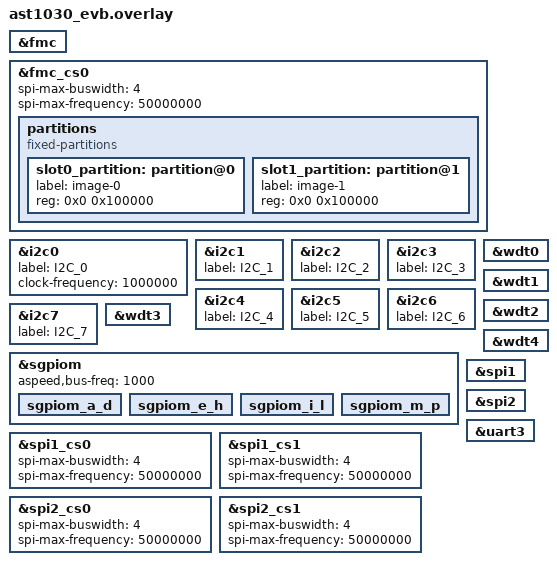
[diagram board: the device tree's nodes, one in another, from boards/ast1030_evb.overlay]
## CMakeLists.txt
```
# Copyright (c) 2026 ASPEED Technology Inc.
# SPDX-License-Identifier: MIT

cmake_minimum_required(VERSION 3.20.0)

find_package(Zephyr REQUIRED HINTS $ENV{ZEPHYR_BASE})
project(obmf-demo)

target_sources(app PRIVATE
    src/main.c
    src/lstp_usb.c
    src/lstp_router.c
    src/lstp_task.c
    src/lstp_i2c.c
    src/lstp_spi.c
    src/lstp_uart.c
)
```

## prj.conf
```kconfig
CONFIG_LOG=y
# CONFIG_LOG_MODE_IMMEDIATE=y
# CONFIG_LOG_DEFAULT_LEVEL=4
CONFIG_UART_CONSOLE_DEBUG_SERVER_HOOKS=y

# USB configuration
CONFIG_USB_DEVICE_STACK=y
CONFIG_USB_DEVICE_PRODUCT="OBMF Demo"
CONFIG_USB_DEVICE_VID=0x1ab4
CONFIG_USB_DEVICE_PID=0x0001
# Use same max EP buffer size as mctp-demo if 512 is supported, or fallback to 64 if HS is not enabled
CONFIG_USB_DEVICE_INITIALIZE_AT_BOOT=n
CONFIG_SHELL=y
CONFIG_SHELL_PROMPT_UART="ast1030-evb:~$ "
CONFIG_SHELL_STACK_SIZE=4096
CONFIG_SHELL_BACKEND_SERIAL_INIT_PRIORITY=99
CONFIG_SHELL_BACKEND_SERIAL_LOG_MESSAGE_QUEUE_TIMEOUT=-1
CONFIG_SHELL_BACKEND_SERIAL_LOG_MESSAGE_QUEUE_SIZE=1024

# I2C support for the OBMF I2C channel
CONFIG_I2C=y
CONFIG_UART_INTERRUPT_DRIVEN=y
```

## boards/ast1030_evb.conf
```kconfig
CONFIG_WATCHDOG=y
CONFIG_DYNAMIC_INTERRUPTS=y
CONFIG_GPIO_ASPEED_SGPIOM=y

CONFIG_SPI=y
CONFIG_SPI_ASPEED=y
CONFIG_SPI_NOR=n
CONFIG_SPI_NOR_MULTI_DEV=y
CONFIG_SPI_DMA_SUPPORT_ASPEED=y

CONFIG_FLASH=y
CONFIG_FLASH_JESD216_API=y
CONFIG_FLASH_PAGE_LAYOUT=y
CONFIG_FLASH_MAP=y
CONFIG_FLASH_SHELL=y

CONFIG_I2C=y
CONFIG_I2C_ASPEED=y
CONFIG_I2C_TARGET=y


CONFIG_USB_CDC_ACM=n
# For the NVIDIA OBMF USB host driver
CONFIG_USB_DEVICE_VID=0x0955
CONFIG_USB_DEVICE_PID=0xcf11
CONFIG_USB_DEVICE_MANUFACTURER="ASPEED"
CONFIG_USB_DEVICE_PRODUCT="OBMF-USB"
CONFIG_USB_DEVICE_SN="55661030"
CONFIG_USB_DEVICE_STACK=y
CONFIG_USB_REQUEST_BUFFER_SIZE=4096
# CONFIG_USB_DEVICE_LOG_LEVEL_OFF=y

CONFIG_I3C=y
CONFIG_I3C_TARGET=y
CONFIG_I3C_IBI_WORKQUEUE=y
CONFIG_I3C_SHELL=y
CONFIG_SHELL_GETOPT=y


CONFIG_MBEDTLS=n
CONFIG_MBEDTLS_SHA384=n
CONFIG_UART_ASPEED=y


CONFIG_JTAG=y
CONFIG_JTAG_ASPEED=y

CONFIG_USB_WORKQUEUE=y
```

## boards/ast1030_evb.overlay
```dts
&fmc {
	status = "okay";
};

&fmc_cs0 {
	status = "okay";
	spi-max-buswidth = <4>;
	spi-max-frequency = <50000000>;

	partitions {
		compatible = "fixed-partitions";
		#address-cells = <1>;
		#size-cells = <1>;
		slot0_partition: partition@0 {
			label = "image-0";
			reg = <0x0 0x100000>;
		};
		slot1_partition: partition@1 {
		       label = "image-1";
		       reg = <0x0 0x100000>;
	       };
	};
};

&i2c0 {
	status = "okay";
	label = "I2C_0";
	clock-frequency = <1000000>;
};

&i2c1 {
	status = "okay";
	label = "I2C_1";
};

&i2c2 {
	status = "okay";
	label = "I2C_2";
};

&i2c3 {
	status = "okay";
	label = "I2C_3";
};

&i2c4 {
	status = "okay";
	label = "I2C_4";
};

&i2c5 {
	status = "okay";
	label = "I2C_5";
};

&i2c6 {
	status = "okay";
	label = "I2C_6";
};

&i2c7 {
	status = "okay";
	label = "I2C_7";
};

&wdt0 {
	status = "okay";
};

&wdt1 {
	status = "okay";
};

&wdt2 {
	status = "okay";
};

&wdt3 {
	status = "okay";
};

&wdt4 {
	status = "okay";
};

/*
 * i3c0-to-i3c1 Loopback:
 * i3c0 plays the role as the bus controller
 * i3c1 plays the rols as the target device
 *
 * In I3C shell command, the following devices will be found:
 * i3c@7e7a2000 -> i3c0 controller
 * i3cdev@7ec80011000 -> the i3c device attached to i3c0 controller
 *
 * i3c@7e7a2000 -> i3c1 controller
 * i3c-tmq@7ec80011000 -> i3c target mqueue device
 */
// &i3c0 {
// 	status = "okay";
// 	label = "I3C_0";
// 	sda-tx-hold-ns = <20>;
// 	i3c-pp-scl-hi-period-ns = <250>;
// 	i3c-pp-scl-lo-period-ns = <250>;
//
// 	assigned-address = <0x30>;
//
// 	i3cdev@7ec80011000 {
// 		compatible = "i3c-dummy-device";
// 		reg = <0x0 0x7ec 0x80011000>;
// 		status = "okay";
// 	};
// };

// &i3c1 {
// 	secondary;
// 	dcr = <0xcc>;
// 	status = "okay";
// 	label = "I3C_1";
//
// 	assigned-address = <0x31>;
//
// 	i3c-tmq@7ec80011000 {
// 		compatible = "i3c-target-mqueue";
// 		reg = <0x0 0x7ec 0x80011000>;
// 		msg-size = <128>;
// 		num-of-msgs = <4>;
// 		mandatory-data-byte = <0xbf>;
// 		status = "okay";
// 	};
// };

&sgpiom {
	status = "okay";
	aspeed,bus-freq = <1000>;

	sgpiom_a_d {
		status = "okay";
	};
	sgpiom_e_h {
		status = "okay";
	};
	sgpiom_i_l {
		status = "okay";
	};
	sgpiom_m_p {
		status = "okay";
	};
};

&spi1 {
	status = "okay";
};

&spi1_cs0 {
	status = "okay";
	spi-max-buswidth = <4>;
	spi-max-frequency = <50000000>;
};

&spi1_cs1 {
	status = "okay";
	spi-max-buswidth = <4>;
	spi-max-frequency = <50000000>;
};

&spi2 {
	status = "okay";
};

&spi2_cs0 {
	status = "okay";
	spi-max-buswidth = <4>;
	spi-max-frequency = <50000000>;
};

&spi2_cs1 {
	status = "okay";
	spi-max-buswidth = <4>;
	spi-max-frequency = <50000000>;
};

&uart3 {
	status = "okay";
};
```

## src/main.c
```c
/*
 * Copyright (c) 2026 ASPEED Technology Inc.
 *
 * SPDX-License-Identifier: Apache-2.0
 */

#include <zephyr/kernel.h>
#include <zephyr/logging/log.h>
#include <zephyr/usb/usb_device.h>
#include "lstp_router.h"
#include "lstp_spi.h"
#include "lstp_task.h"
#include "lstp_uart.h"
#include "lstp_usb.h"

LOG_MODULE_REGISTER(main, LOG_LEVEL_INF);

int main(void)
{
	LOG_INF("Starting obmf-demo application");

	/* Initialize the OBMF transport router */
	lstp_router_init();

	/* Initialize the background hardware task */
	lstp_task_init();

	int ret = lstp_spi_init();
	if (ret != 0) {
		LOG_ERR("Failed to initialize SPI SFDP cache: %d", ret);
	}

	/* Initialize the USB transport for OBMF */
	ret = lstp_usb_init();
	if (ret != 0) {
		LOG_ERR("Failed to initialize USB subsystem: %d", ret);
		return ret;
	}

	ret = lstp_uart_init();
	if (ret != 0) {
		LOG_ERR("Failed to initialize OBMF UART backend: %d", ret);
		return ret;
	}

	LOG_INF("obmf-demo application running");

	/* Main loop: We can suspend or do background tasks here,
	 * as USB operations are handled via callbacks and separate threads.
	 */
	while (1) {
		k_sleep(K_SECONDS(1));
	}

	return 0;
}
```

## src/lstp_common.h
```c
/*
 * SPDX-FileCopyrightText: Copyright (c) 2026 NVIDIA CORPORATION & AFFILIATES.
 * SPDX-FileCopyrightText: Copyright (c) 2026 ASPEED Technology Inc.
 *
 * SPDX-License-Identifier: Apache-2.0
 *
 * Portions derived from NVIDIA OpenSMA (https://github.com/NVIDIA/OpenSMA),
 * licensed under Apache-2.0. Ported and modified by ASPEED.
 */
#ifndef LSTP_COMMON_H
#define LSTP_COMMON_H

#include <stdint.h>
#include <stddef.h>
#include <stdbool.h>

#ifdef __cplusplus
extern "C" {
#endif

/*****************************************************
 * Bit manipulation constants
 *****************************************************/
#define BYTE1_SHIFT 8
#define BYTE2_SHIFT 16
#define BYTE3_SHIFT 24
#define LSB_MASK    0xff
#define MSB_MASK    0xff00

/*****************************************************
 * LSTP General
 *****************************************************/
#define LSTP_VERSION      1
#define LSTP_MAX_CHANNELS 255
#define LSTP_NUM_CHANNELS 5

typedef enum {
	LSTP_CHANNEL_TYPE_MANAGEMENT = 0,
	LSTP_CHANNEL_TYPE_SPI        = 1,
	LSTP_CHANNEL_TYPE_GPIO       = 2,
	LSTP_CHANNEL_TYPE_I2C        = 3,
	LSTP_CHANNEL_TYPE_UART       = 4,
	LSTP_CHANNEL_TYPE_IPMI       = 5
} lstp_channel_type_t;

typedef enum {
	LSTP_STATUS_SUCCESS       = 0x00,
	LSTP_STATUS_ERROR         = 0x01,
	LSTP_STATUS_TIMEOUT       = 0x02,
	LSTP_STATUS_BUSY          = 0x03,
	LSTP_STATUS_NAK           = 0x04,
	LSTP_STATUS_ARB_LOST      = 0x05,
	LSTP_STATUS_NOT_SUPPORTED = 0x06,
	LSTP_STATUS_IRQ_INTERRUPT = 0xFF,
} lstp_status_t;

#define LSTP_RESPONSE_BIT 0x80

struct lstp_hdr {
	uint8_t channel_id;
	uint8_t cmd_status_code;  /* Bit 7 is reserved for request (=0) and response (=1) flag */
	uint8_t len_lsb;
	uint8_t len_msb;
} __attribute__((packed));

#define LSTP_MSG_SIZE         512
#define LSTP_MAX_PAYLOAD_SIZE (LSTP_MSG_SIZE - sizeof(struct lstp_hdr))

struct lstp_channel_config_write_request {
	uint8_t  channel_id;
	uint16_t offset;
} __attribute__((packed));

struct lstp_channel_config_read_request {
	uint8_t  channel_id;
	uint16_t offset;
	uint16_t length;
} __attribute__((packed));

struct lstp_channel_config_blob {
	uint8_t channel_type;
	uint8_t channel_enabled;
	uint8_t channel_name[16];
	/* Followed by channel-specific config data */
} __attribute__((packed));

/*****************************************************
 * LSTP Management Channel (Ch0)
 *****************************************************/
typedef enum {
	LSTP_MGMT_CMD_READ_CONFIG  = 0x08,
	LSTP_MGMT_CMD_WRITE_CONFIG = 0x09,
	LSTP_MGMT_CMD_LOCK         = 0x0A,
} lstp_management_cmd_t;

struct lstp_management_config {
	uint8_t lstp_version;
	uint8_t num_channels;
} __attribute__((packed));

/*****************************************************
 * LSTP GPIO Channel
 *****************************************************/

/**
 * Number of logical GPIO indices exposed over LSTP.
 * Currently maps to one SGPIO block (sgpiom_a_d, pins 0-31).
 */
#define LSTP_GPIO_NUM 128

/**
 * Mask to strip the response/request bit (bit 7) from cmd_status_code
 * before interpreting it as a GPIO command.
 * Matches OpenSMA's LstpGpioCmdMask = 0x7F.
 */
#define LSTP_GPIO_CMD_MASK 0x7F

#define LSTP_GPIO_NAME_MAX_LEN    32U
/** Maximum GPIO entries per LSTP packet (capacity guard). */
#define LSTP_MAX_GPIOS_PER_PACKET 10U

typedef enum {
	LSTP_GPIO_DIRECTION_OUTPUT = 0,
	LSTP_GPIO_DIRECTION_INPUT  = 1,
} lstp_gpio_direction_t;

typedef enum {
	LSTP_GPIO_OUTPUT_DRIVE_PUSH_PULL   = 0,
	LSTP_GPIO_OUTPUT_DRIVE_OPEN_DRAIN  = 1,
	LSTP_GPIO_OUTPUT_DRIVE_OPEN_SOURCE = 2,
} lstp_gpio_output_drive_config_t;

typedef enum {
	LSTP_GPIO_BIAS_NO_PULL   = 0,
	LSTP_GPIO_BIAS_PULL_UP   = 1,
	LSTP_GPIO_BIAS_PULL_DOWN = 2,
} lstp_gpio_bias_pull_config_t;

typedef enum {
	LSTP_GPIO_CMD_GET_VALUE      = 0x00,
	LSTP_GPIO_CMD_SET_VALUE      = 0x01,
	LSTP_GPIO_CMD_GET_IRQ_CONFIG = 0x02,
	LSTP_GPIO_CMD_SET_IRQ_CONFIG = 0x03,
	LSTP_GPIO_CMD_IRQ_EVENT      = 0x04,
} lstp_gpio_command_t;

typedef enum {
	LSTP_GPIO_STATE_LOW  = 0,
	LSTP_GPIO_STATE_HIGH = 1,
} lstp_gpio_state_t;

typedef enum {
	LSTP_GPIO_IRQ_DISABLED  = 0,
	LSTP_GPIO_IRQ_RISING    = 1,
	LSTP_GPIO_IRQ_FALLING   = 2,
	LSTP_GPIO_IRQ_BOTH_EDGE = 3,
	LSTP_GPIO_IRQ_HIGH      = 4,
	LSTP_GPIO_IRQ_LOW       = 5,
	LSTP_GPIO_IRQ_MAX       = LSTP_GPIO_IRQ_LOW,
} lstp_gpio_irq_config_t;

/**
 * Appended after lstp_channel_config_blob in a ReadConfig response
 * for the GPIO channel, matching OpenSMA's LstpGpioChannelConfig.
 */
struct lstp_gpio_channel_config {
	uint8_t channel_num_gpio;
	/* Optionally followed by channel_num_gpio * lstp_gpio_config entries */
} __attribute__((packed));

struct lstp_gpio_config {
	uint8_t  gpio_name[LSTP_GPIO_NAME_MAX_LEN];
	uint8_t  direction;             /* lstp_gpio_direction_t */
	uint8_t  default_output;        /* lstp_gpio_state_t */
	uint8_t  output_drive_config;   /* lstp_gpio_output_drive_config_t */
	uint8_t  output_persist_state;  /* bool */
	uint8_t  bias_pull_config;      /* lstp_gpio_bias_pull_config_t */
	uint16_t bias_pull_strength;    /* 16 ohm increments */
	uint16_t output_drive_strength; /* mA */
	uint16_t slew_rate;             /* 100 ps increments */
	uint16_t input_debounce_time;   /* us */
	uint8_t  rsvd_0;
	uint8_t  rsvd_1;
	uint8_t  rsvd_2;
} __attribute__((packed));

_Static_assert(sizeof(struct lstp_gpio_config) == 48,
	       "lstp_gpio_config size must be 48 bytes");

/* ---- GetValue ---- */
/* Request:  [gpio_index : uint16_t] per GPIO (2 bytes each)
 * Response: [value : uint8_t]       per GPIO (1 byte each) */
struct lstp_gpio_get_value_request {
	uint16_t gpio_index;
} __attribute__((packed));

struct lstp_gpio_get_value_response {
	uint8_t value; /* lstp_gpio_state_t */
} __attribute__((packed));

/* ---- SetValue ---- */
/* Request:  [gpio_index : uint16_t, value : uint8_t] per GPIO (3 bytes each)
 * Response: empty payload on success */
struct lstp_gpio_set_value_request {
	uint16_t gpio_index;
	uint8_t  value; /* lstp_gpio_state_t */
} __attribute__((packed));

/* ---- GetIrqConfig ---- */
/* Request:  [gpio_index : uint16_t] (2 bytes)
 * Response: [irq_type : uint8_t]   (1 byte) */
struct lstp_gpio_get_irq_config_request {
	uint16_t gpio_index;
} __attribute__((packed));

struct lstp_gpio_get_irq_config_response {
	uint8_t irq_type; /* lstp_gpio_irq_config_t */
} __attribute__((packed));

/* ---- SetIrqConfig ---- */
/* Request:  [gpio_index : uint16_t, irq_type : uint8_t] (3 bytes)
 * Response: empty payload on success */
struct lstp_gpio_set_irq_config_request {
	uint16_t gpio_index;
	uint8_t  irq_type; /* lstp_gpio_irq_config_t */
} __attribute__((packed));

/* ---- IrqEvent (firmware → host unsolicited) ---- */
/* Payload: [gpio_index : uint16_t, value : uint8_t] (3 bytes) */
struct lstp_gpio_irq_event_request {
	uint16_t gpio_index;
	uint8_t  value; /* lstp_gpio_state_t */
} __attribute__((packed));

/*****************************************************
 * LSTP SPI Channel
 *****************************************************/

#define LSTP_SPI_MAX_CS 4

struct lstp_spi_channel_config {
	uint8_t  channel_num_cs;
	uint32_t freq_hz;
} __attribute__((packed));

/**
 * SPI command codes, matching OpenSMA's FlashromCmdCode.
 * Command byte layout:
 *   Bits [7:6] = CS select (SPI_CS_MASK)
 *   Bit  [5]   = CS deassert flag (SPI_CS_DEASSERT)
 *   Bit  [4]   = CS assert flag (SPI_CS_ASSERT)
 *   Bits [3:0] = Command code (CMD_CODE_MASK)
 */
#define LSTP_SPI_CMD_CODE_MASK   0x0F
#define LSTP_SPI_CS_ASSERT       0x20
#define LSTP_SPI_CS_DEASSERT     0x10
#define LSTP_SPI_CS_MASK         0xC0
#define LSTP_SPI_CS0             0x00
#define LSTP_SPI_CS1             0x40
#define LSTP_SPI_CS2             0x80
#define LSTP_SPI_CS3             0xC0

typedef enum {
	LSTP_SPI_CMD_CONFIG       = 0x00,
	LSTP_SPI_CMD_READ         = 0x01,
	LSTP_SPI_CMD_WRITE        = 0x02,
	LSTP_SPI_CMD_WRITE_READ   = 0x03,
	LSTP_SPI_CMD_POSTED_WRITE = 0x04,
	LSTP_SPI_CMD_END          = 0x07,
	LSTP_SPI_CMD_SUCCESS_RSP  = 0x80  /* Used in response cmd_status_code */
} lstp_spi_command_t;

/* ---- Config ---- */
/* Request:  empty payload
 * Response: [speed_hz : uint32_t] (4 bytes, little-endian) */

/* ---- Read ---- */
/* Request:  [read_count : uint32_t] (4 bytes, little-endian)
 * Response: [read_count bytes] in one or more packets */

/* ---- Write ---- */
/* Request:  [N bytes of write data]
 * Response: [0x00] (1 byte status) */

/* ---- WriteRead ---- */
/* Request:  [M bytes of write data]
 * Response: [M bytes of read data] */

/* ---- PostedWrite ---- */
/* Request:  [N bytes of write data]
 * Response: none (fire-and-forget) */

/*****************************************************
 * LSTP I2C Channel
 *****************************************************/

typedef enum {
	LSTP_I2C_SPEED_STANDARD = 0x00,  /* 100 kHz */
	LSTP_I2C_SPEED_FAST     = 0x01,  /* 400 kHz */
	LSTP_I2C_SPEED_FAST_PLUS= 0x02,  /* 1 MHz */
	LSTP_I2C_SPEED_HIGH     = 0x03,  /* 3.4 MHz */
} lstp_i2c_speed_t;

struct lstp_i2c_channel_config {
	uint8_t speed; /* lstp_i2c_speed_t */
} __attribute__((packed));

/**
 * Mask for the I2C command in cmd_status_code.
 * Bit 7 = response/request flag, Bit 6 = NoStop flag (must be masked off).
 * Matches OpenSMA: LstpI2cCmdMask = 0xBF
 */
#define LSTP_I2C_CMD_MASK    0xBF
/** Bit 6 of cmd_status_code: if set, don't send STOP condition after transfer. */
#define LSTP_I2C_NOSTOP_FLAG 0x40

typedef enum {
	LSTP_I2C_CMD_BUS_RECOVERY  = 0x00,
	LSTP_I2C_CMD_READ          = 0x01,
	LSTP_I2C_CMD_WRITE         = 0x02,
	LSTP_I2C_CMD_READ_RECV_LEN = 0x03,
	LSTP_I2C_CMD_WRITE_READ    = 0x04,
} lstp_i2c_command_t;

/* ---- Read ---- */
/* Request:  {address : uint8_t, read_len : uint16_t} (3 bytes)
 * Response: [read_len bytes of data] */
struct lstp_i2c_read_request {
	uint8_t  address;
	uint16_t read_len;
} __attribute__((packed));

/* ---- Write ---- */
/* Request:  {address : uint8_t} followed by N bytes of write data
 * Response: empty on success */
struct lstp_i2c_write_request {
	uint8_t address;
	/* Followed by N bytes of write data */
} __attribute__((packed));

/* ---- ReadRecvLen (SMBus block read) ---- */
/* Request:  {address : uint8_t} (1 byte)
 * Response: first byte received is the length, followed by that many bytes */
struct lstp_i2c_read_recv_len_request {
	uint8_t address;
} __attribute__((packed));

/* ---- WriteRead ---- */
/* Request:  {address : uint8_t, read_len : uint16_t} followed by M bytes of write data
 * Response: [read_len bytes of data] */
struct lstp_i2c_write_read_request {
	uint8_t  address;
	uint16_t read_len;
	/* Followed by M bytes of write data */
} __attribute__((packed));

/*****************************************************
 * LSTP UART Channel
 *****************************************************/

typedef enum {
	LSTP_UART_CMD_WRITE = 0x00,
} lstp_uart_command_t;

struct lstp_uart_channel_config {
} __attribute__((packed));

#ifdef __cplusplus
}
#endif

#endif /* LSTP_COMMON_H */
```

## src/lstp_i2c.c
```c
/*
 * SPDX-FileCopyrightText: Copyright (c) 2026 NVIDIA CORPORATION & AFFILIATES.
 * SPDX-FileCopyrightText: Copyright (c) 2026 ASPEED Technology Inc.
 *
 * SPDX-License-Identifier: Apache-2.0
 *
 * Portions derived from NVIDIA OpenSMA (https://github.com/NVIDIA/OpenSMA),
 * licensed under Apache-2.0. Ported and modified by ASPEED.
 */

#include <zephyr/kernel.h>
#include <zephyr/logging/log.h>
#include <zephyr/drivers/i2c.h>
#include <string.h>

#include "lstp_common.h"
#include "lstp_i2c.h"

LOG_MODULE_REGISTER(lstp_i2c, LOG_LEVEL_ERR);

/* -----------------------------------------------------------------------
 * I2C channel → Zephyr device binding table
 *
 * LSTP channel 2 is the first (and only) I2C channel, mapped to i2c0.
 * This is the Zephyr equivalent of OpenSMA's compile-time GpioSetup table.
 *
 * To add more buses, extend this array and add cases in handle_read_config.
 * ----------------------------------------------------------------------- */
#define LSTP_I2C_CHANNEL_START 2   /* First LSTP channel ID used for I2C */
#define LSTP_I2C_NUM_CHANNELS  1   /* Number of I2C channels exposed */

static const struct device *lstp_i2c_devs[LSTP_I2C_NUM_CHANNELS] = {
	DEVICE_DT_GET(DT_NODELABEL(i2c6)),  /* LSTP channel 2 → i2c6 */
};

/* -----------------------------------------------------------------------
 * Helpers
 * ----------------------------------------------------------------------- */

static const struct device *get_i2c_dev(uint8_t channel_id)
{
	int idx = (int)channel_id - LSTP_I2C_CHANNEL_START;

	if (idx < 0 || idx >= LSTP_I2C_NUM_CHANNELS) {
		return NULL;
	}
	return lstp_i2c_devs[idx];
}

static lstp_status_t zephyr_ret_to_lstp(int ret)
{
	if (ret == 0) {
		return LSTP_STATUS_SUCCESS;
	}
	if (ret == -ETIMEDOUT) {
		return LSTP_STATUS_TIMEOUT;
	}
	if (ret == -EBUSY) {
		return LSTP_STATUS_BUSY;
	}
	return LSTP_STATUS_ERROR;
}

/* -----------------------------------------------------------------------
 * lstp_i2c_receive
 *
 * Implements OpenSMA's LstpRouter::receive_i2c synchronously.
 *
 * Request header layout (from OpenSMA lstp_common.h):
 *   cmd_status_code bits:
 *     [7]   = request/response bit (already stripped by caller)
 *     [6]   = NoStop flag (I2C_MSG_RESTART instead of I2C_MSG_STOP)
 *     [5:0] = command (LSTP_I2C_CMD_MASK = 0xBF strips bits 7 and 6)
 *
 * Note: read_len in OpenSMA is bounded to LstpMaxPayloadSize. We enforce
 * the same limit (LSTP_MAX_PAYLOAD_SIZE).
 * ----------------------------------------------------------------------- */
lstp_status_t lstp_i2c_receive(uint8_t channel_id,
				struct lstp_hdr *hdr,
				uint8_t *payload, size_t payload_len,
				uint8_t *resp_payload, size_t *resp_payload_len)
{
	*resp_payload_len = 0;

	const struct device *dev = get_i2c_dev(channel_id);

	if (!dev || !device_is_ready(dev)) {
		LOG_ERR("I2C dev for channel %d not ready", channel_id);
		return LSTP_STATUS_ERROR;
	}

	if (payload_len > LSTP_MAX_PAYLOAD_SIZE) {
		return LSTP_STATUS_ERROR;
	}

	lstp_i2c_command_t cmd =
		(lstp_i2c_command_t)(hdr->cmd_status_code & LSTP_I2C_CMD_MASK);

	/* Bit 6: NoStop — use I2C repeated-start (no STOP between write and read) */
	bool no_stop = (hdr->cmd_status_code & LSTP_I2C_NOSTOP_FLAG) != 0;

	int ret = 0;

	switch (cmd) {

	/* ------------------------------------------------------------------
	 * BusRecovery — not supported (matches OpenSMA)
	 * ------------------------------------------------------------------ */
	case LSTP_I2C_CMD_BUS_RECOVERY:
		return LSTP_STATUS_NOT_SUPPORTED;

	/* ------------------------------------------------------------------
	 * Read: {address, read_len} → [read_len bytes]
	 * QuickRead (read_len == 0): address probe with zero-length read.
	 * Matches OpenSMA receive_i2c LstpI2cCommand::Read.
	 * ------------------------------------------------------------------ */
	case LSTP_I2C_CMD_READ: {
		if (payload_len < sizeof(struct lstp_i2c_read_request)) {
			return LSTP_STATUS_ERROR;
		}

		const struct lstp_i2c_read_request *req =
			(const struct lstp_i2c_read_request *)payload;
		uint16_t read_len = req->read_len;

		if (read_len > LSTP_MAX_PAYLOAD_SIZE) {
			return LSTP_STATUS_ERROR;
		}

		if (read_len == 0) {
			/* QuickRead: address probe, zero-length, just send STOP */
			struct i2c_msg msg = {
				.buf   = resp_payload,
				.len   = 0,
				.flags = I2C_MSG_READ | I2C_MSG_STOP,
			};
			ret = i2c_transfer(dev, &msg, 1, req->address);
		} else {
			ret = i2c_read(dev, resp_payload, read_len, req->address);
		}

		if (ret == 0) {
			*resp_payload_len = read_len;
		}

		LOG_DBG("I2C Read addr=0x%02x len=%u ret=%d", req->address, read_len, ret);
		return zephyr_ret_to_lstp(ret);
	}

	/* ------------------------------------------------------------------
	 * Write: {address} + N bytes → empty response
	 * QuickWrite (N == 0): address probe with zero-length write.
	 * Matches OpenSMA receive_i2c LstpI2cCommand::Write.
	 * ------------------------------------------------------------------ */
	case LSTP_I2C_CMD_WRITE: {
		if (payload_len < sizeof(struct lstp_i2c_write_request)) {
			return LSTP_STATUS_ERROR;
		}

		const struct lstp_i2c_write_request *req =
			(const struct lstp_i2c_write_request *)payload;
		uint8_t *write_data = payload + sizeof(struct lstp_i2c_write_request);
		size_t   write_len  = payload_len - sizeof(struct lstp_i2c_write_request);

		if (write_len == 0) {
			/*
			 * QuickWrite: the host is probing device presence.
			 *
			 * Use i2c_write_read (write reg 0, read 1 byte) — this is
			 * exactly what the Zephyr I2C shell `read_byte` does.  A bare
			 * i2c_read or zero-length write both fail on devices that
			 * require a register address write phase before responding.
			 */
			uint8_t reg = 0;
			uint8_t dummy;
			ret = i2c_write_read(dev, req->address, &reg, 1, &dummy, 1);
			LOG_DBG("QuickWrite probe (write_read reg0) addr=0x%02x ret=%d",
				req->address, ret);
		} else if (no_stop) {
			/*
			 * NoStop (repeated-start): send write without STOP.
			 * Matches OpenSMA's I2cFlags::NoStop.
			 */
			struct i2c_msg msg = {
				.buf   = write_data,
				.len   = write_len,
				.flags = I2C_MSG_WRITE,
			};
			ret = i2c_transfer(dev, &msg, 1, req->address);
		} else {
			ret = i2c_write(dev, write_data, write_len, req->address);
		}

		LOG_DBG("I2C Write addr=0x%02x len=%zu ret=%d",
			req->address, write_len, ret);
		return zephyr_ret_to_lstp(ret);
	}

	/* ------------------------------------------------------------------
	 * ReadRecvLen: {address} → SMBus block read.
	 * First received byte is the count, followed by that many bytes.
	 * Matches OpenSMA receive_i2c LstpI2cCommand::ReadRecvLen.
	 * ------------------------------------------------------------------ */
	case LSTP_I2C_CMD_READ_RECV_LEN: {
		if (payload_len < sizeof(struct lstp_i2c_read_recv_len_request)) {
			return LSTP_STATUS_ERROR;
		}

		const struct lstp_i2c_read_recv_len_request *req =
			(const struct lstp_i2c_read_recv_len_request *)payload;

		/*
		 * Read the full max payload into the response buffer.
		 * The first byte returned is the byte count (SMBus convention).
		 * OpenSMA reads (UsbLstpMsgSize - sizeof(LstpHdr)) bytes.
		 */
		uint16_t read_len = (uint16_t)LSTP_MAX_PAYLOAD_SIZE;

		ret = i2c_read(dev, resp_payload, read_len, req->address);
		if (ret == 0) {
			/* Clamp actual response to count byte + data */
			uint8_t count = resp_payload[0];
			*resp_payload_len = 1U + (size_t)count;
			if (*resp_payload_len > LSTP_MAX_PAYLOAD_SIZE) {
				*resp_payload_len = LSTP_MAX_PAYLOAD_SIZE;
			}
		}

		LOG_DBG("I2C ReadRecvLen addr=0x%02x ret=%d", req->address, ret);
		return zephyr_ret_to_lstp(ret);
	}

	/* ------------------------------------------------------------------
	 * WriteRead: {address, read_len} + M bytes → [read_len bytes]
	 * Matches OpenSMA receive_i2c LstpI2cCommand::WriteRead.
	 * ------------------------------------------------------------------ */
	case LSTP_I2C_CMD_WRITE_READ: {
		if (payload_len < sizeof(struct lstp_i2c_write_read_request)) {
			return LSTP_STATUS_ERROR;
		}

		const struct lstp_i2c_write_read_request *req =
			(const struct lstp_i2c_write_read_request *)payload;
		uint8_t *write_data = payload + sizeof(struct lstp_i2c_write_read_request);
		size_t   write_len  =
			payload_len - sizeof(struct lstp_i2c_write_read_request);
		uint16_t read_len   = req->read_len;

		if (read_len > LSTP_MAX_PAYLOAD_SIZE) {
			return LSTP_STATUS_ERROR;
		}

		ret = i2c_write_read(dev, req->address,
				     write_data, write_len,
				     resp_payload, read_len);
		if (ret == 0) {
			*resp_payload_len = read_len;
		}

		LOG_DBG("I2C WriteRead addr=0x%02x wlen=%zu rlen=%u ret=%d",
			req->address, write_len, read_len, ret);
		return zephyr_ret_to_lstp(ret);
	}

	default:
		return LSTP_STATUS_NOT_SUPPORTED;
	}
}
```

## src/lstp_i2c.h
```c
/*
 * SPDX-FileCopyrightText: Copyright (c) 2026 NVIDIA CORPORATION & AFFILIATES.
 * SPDX-FileCopyrightText: Copyright (c) 2026 ASPEED Technology Inc.
 *
 * SPDX-License-Identifier: Apache-2.0
 *
 * Portions derived from NVIDIA OpenSMA (https://github.com/NVIDIA/OpenSMA),
 * licensed under Apache-2.0. Ported and modified by ASPEED.
 */

#ifndef LSTP_I2C_H
#define LSTP_I2C_H

#include <stdint.h>
#include <stddef.h>
#include "lstp_common.h"

/**
 * @brief Handle an incoming LSTP I2C channel request.
 *
 * Executes the I2C transfer synchronously (Read/Write/ReadRecvLen/WriteRead)
 * and fills the response payload. Mirrors OpenSMA's LstpRouter::receive_i2c.
 *
 * @param channel_id  LSTP channel ID (used to select the I2C bus)
 * @param hdr         Pointer to the request LSTP header
 * @param payload     Pointer to the request payload (after header)
 * @param payload_len Length of the request payload in bytes
 * @param resp_payload Output buffer for the response payload (after header)
 * @param resp_payload_len Set to the number of bytes written to resp_payload
 * @return LSTP status code
 */
lstp_status_t lstp_i2c_receive(uint8_t channel_id,
				struct lstp_hdr *hdr,
				uint8_t *payload, size_t payload_len,
				uint8_t *resp_payload, size_t *resp_payload_len);

#endif /* LSTP_I2C_H */
```

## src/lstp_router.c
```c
/*
 * SPDX-FileCopyrightText: Copyright (c) 2026 NVIDIA CORPORATION & AFFILIATES.
 * SPDX-FileCopyrightText: Copyright (c) 2026 ASPEED Technology Inc.
 *
 * SPDX-License-Identifier: Apache-2.0
 *
 * Portions derived from NVIDIA OpenSMA (https://github.com/NVIDIA/OpenSMA),
 * licensed under Apache-2.0. Ported and modified by ASPEED.
 */

#include <zephyr/kernel.h>
#include <zephyr/logging/log.h>
#include <zephyr/sys/printk.h>
#include <string.h>

#include "lstp_common.h"
#include "lstp_router.h"
#include "lstp_uart.h"
#include "lstp_usb.h"
#include "lstp_task.h"

LOG_MODULE_REGISTER(lstp_router, LOG_LEVEL_ERR);

struct lstp_channel_state {
	bool enabled;
};

static struct lstp_channel_state channels[LSTP_MAX_CHANNELS];

static bool channel_id_supported(uint8_t channel_id)
{
	return channel_id < LSTP_NUM_CHANNELS;
}

static void fill_gpio_config(uint16_t gpio_index, struct lstp_gpio_config *cfg)
{
	memset(cfg, 0, sizeof(*cfg));
	snprintk((char *)cfg->gpio_name, sizeof(cfg->gpio_name), "GPIO%u", gpio_index);
	cfg->direction = LSTP_GPIO_DIRECTION_OUTPUT;
	cfg->default_output = LSTP_GPIO_STATE_LOW;
	cfg->output_drive_config = LSTP_GPIO_OUTPUT_DRIVE_PUSH_PULL;
	cfg->output_persist_state = 0;
	cfg->bias_pull_config = LSTP_GPIO_BIAS_NO_PULL;
}

static lstp_status_t read_gpio_config_helper(uint16_t req_offset, uint16_t req_length,
					     uint8_t *resp_buf, size_t *resp_len)
{
	uint16_t start_pin = 0;
	uint16_t n_pins = 0;
	size_t offset = 0;

	if (req_offset == 0) {
		struct lstp_gpio_channel_config *gpio_cfg =
			(struct lstp_gpio_channel_config *)(resp_buf + offset);
		gpio_cfg->channel_num_gpio = LSTP_GPIO_NUM;
		offset += sizeof(*gpio_cfg);

		if (req_length == 0) {
			n_pins = MIN(LSTP_GPIO_NUM, LSTP_MAX_GPIOS_PER_PACKET);
		} else {
			if (req_length < sizeof(struct lstp_gpio_channel_config)) {
				return LSTP_STATUS_ERROR;
			}
			if ((req_length - sizeof(struct lstp_gpio_channel_config))
			    % sizeof(struct lstp_gpio_config) != 0) {
				return LSTP_STATUS_ERROR;
			}

			n_pins = (req_length - sizeof(struct lstp_gpio_channel_config))
				 / sizeof(struct lstp_gpio_config);
		}
	} else {
		if (req_offset < sizeof(struct lstp_gpio_channel_config)) {
			return LSTP_STATUS_ERROR;
		}
		if ((req_offset - sizeof(struct lstp_gpio_channel_config))
		    % sizeof(struct lstp_gpio_config) != 0) {
			return LSTP_STATUS_ERROR;
		}
		if (req_length % sizeof(struct lstp_gpio_config) != 0) {
			return LSTP_STATUS_ERROR;
		}

		start_pin = (req_offset - sizeof(struct lstp_gpio_channel_config))
			    / sizeof(struct lstp_gpio_config);
		n_pins = req_length / sizeof(struct lstp_gpio_config);
	}

	if (start_pin >= LSTP_GPIO_NUM) {
		return LSTP_STATUS_ERROR;
	}

	if ((size_t)n_pins > LSTP_MAX_GPIOS_PER_PACKET) {
		return LSTP_STATUS_ERROR;
	}

	if ((size_t)start_pin + (size_t)n_pins > LSTP_GPIO_NUM) {
		n_pins = LSTP_GPIO_NUM - start_pin;
	}

	for (uint16_t i = 0; i < n_pins; i++) {
		if (offset + sizeof(struct lstp_gpio_config) > LSTP_MAX_PAYLOAD_SIZE) {
			return LSTP_STATUS_ERROR;
		}

		struct lstp_gpio_config *cfg =
			(struct lstp_gpio_config *)(resp_buf + offset);
		fill_gpio_config(start_pin + i, cfg);
		offset += sizeof(*cfg);
	}

	*resp_len = offset;
	return LSTP_STATUS_SUCCESS;
}

static lstp_status_t write_channel_config_helper(uint8_t channel_id,
						 struct lstp_channel_config_blob *cfg,
						 size_t cfg_size)
{
	size_t cfg_offset = 0;

	if (!channel_id_supported(channel_id)) {
		return LSTP_STATUS_ERROR;
	}

	if (cfg_size < sizeof(cfg->channel_type) + sizeof(cfg->channel_enabled)) {
		return LSTP_STATUS_ERROR;
	}

	cfg_offset += sizeof(cfg->channel_type);
	cfg_offset += sizeof(cfg->channel_enabled);

	switch ((lstp_channel_type_t)cfg->channel_type) {
	case LSTP_CHANNEL_TYPE_MANAGEMENT:
	case LSTP_CHANNEL_TYPE_SPI:
	case LSTP_CHANNEL_TYPE_GPIO:
	case LSTP_CHANNEL_TYPE_I2C:
	case LSTP_CHANNEL_TYPE_UART:
		if ((bool)cfg->channel_enabled != channels[channel_id].enabled) {
			return LSTP_STATUS_NOT_SUPPORTED;
		}
		break;
	default:
		return LSTP_STATUS_NOT_SUPPORTED;
	}

	ARG_UNUSED(cfg_offset);
	return LSTP_STATUS_SUCCESS;
}

void lstp_router_init(void)
{
	LOG_INF("Initializing OBMF Router");
	for (int i = 0; i < LSTP_NUM_CHANNELS; i++) {
		channels[i].enabled = true; // By default all supported channels enabled
	}
}

static lstp_status_t handle_read_config(struct lstp_hdr *req_hdr, uint8_t *payload, size_t payload_len,
		uint8_t *resp_buf, size_t *resp_len)
{
	if (payload_len < sizeof(struct lstp_channel_config_read_request)) {
		return LSTP_STATUS_ERROR;
	}

	struct lstp_channel_config_read_request *req = (struct lstp_channel_config_read_request *)payload;
	if (!channel_id_supported(req->channel_id)) {
		return LSTP_STATUS_ERROR;
	}

	LOG_DBG("Read Config Request for Channel %d", req->channel_id);

	struct lstp_channel_config_blob *resp_blob = (struct lstp_channel_config_blob *)resp_buf;
	size_t offset = sizeof(struct lstp_channel_config_blob);

	memset(resp_blob->channel_name, 0, sizeof(resp_blob->channel_name));

	/* Populate response based on channel ID */
	switch (req->channel_id) {
		case 0: /* Management Channel */
		{
			resp_blob->channel_type = LSTP_CHANNEL_TYPE_MANAGEMENT;
			resp_blob->channel_enabled = channels[0].enabled;
			strncpy((char *)resp_blob->channel_name, "Management", sizeof(resp_blob->channel_name));

			struct lstp_management_config *mgmt_cfg =
				(struct lstp_management_config *)(resp_buf + offset);
			mgmt_cfg->lstp_version = LSTP_VERSION;
			mgmt_cfg->num_channels = LSTP_NUM_CHANNELS - 1;
			offset += sizeof(struct lstp_management_config);
			break;
		}

		case 1: /* SPI Channel — SPI1 */
		{
			resp_blob->channel_type = LSTP_CHANNEL_TYPE_SPI;
			resp_blob->channel_enabled = channels[1].enabled;
			strncpy((char *)resp_blob->channel_name, "SPI1", sizeof(resp_blob->channel_name));

			/*
			 * Temporary kernel workaround: the current host-side SPI
			 * discovery path expects only the base channel blob here and
			 * mis-parses the OpenSMA SPI tail {channel_num_cs, freq_hz}.
			 * Keep the SPI read-config response at 18 bytes until the
			 * kernel-side parser is fixed.
			 *
			 * Original OpenSMA-aligned implementation:
			 * if (offset + sizeof(struct lstp_spi_channel_config)
			 *     > LSTP_MAX_PAYLOAD_SIZE) {
			 *         return LSTP_STATUS_ERROR;
			 * }
			 * struct lstp_spi_channel_config *spi_cfg =
			 *         (struct lstp_spi_channel_config *)(resp_buf + offset);
			 * spi_cfg->channel_num_cs = 2;
			 * spi_cfg->freq_hz = 18750000U;
			 * offset += sizeof(struct lstp_spi_channel_config);
			 */
			break;
		}

		case 2: /* I2C Channel — i2c6 */
			resp_blob->channel_type = LSTP_CHANNEL_TYPE_I2C;
			resp_blob->channel_enabled = channels[2].enabled;
			strncpy((char *)resp_blob->channel_name, "I2C6", sizeof(resp_blob->channel_name));

			if (offset + sizeof(struct lstp_i2c_channel_config) <= LSTP_MAX_PAYLOAD_SIZE) {
				struct lstp_i2c_channel_config *i2c_cfg =
					(struct lstp_i2c_channel_config *)(resp_buf + offset);
				i2c_cfg->speed = LSTP_I2C_SPEED_FAST; /* 400 kHz default */
				offset += sizeof(struct lstp_i2c_channel_config);
			}
			break;

		case 3: /* GPIO Channel */
			resp_blob->channel_type = LSTP_CHANNEL_TYPE_GPIO;
			resp_blob->channel_enabled = channels[3].enabled;
			strncpy((char *)resp_blob->channel_name, "GPIO", sizeof(resp_blob->channel_name));
			{
				size_t gpio_resp_len = 0;
				lstp_status_t gpio_status =
					read_gpio_config_helper(req->offset, req->length,
								resp_buf + offset,
								&gpio_resp_len);
				if (gpio_status != LSTP_STATUS_SUCCESS) {
					return gpio_status;
				}
				*resp_len = offset + gpio_resp_len;
				return LSTP_STATUS_SUCCESS;
			}

		case 4: /* UART Channel */
			resp_blob->channel_type = LSTP_CHANNEL_TYPE_UART;
			resp_blob->channel_enabled = channels[4].enabled;
			strncpy((char *)resp_blob->channel_name, "UART", sizeof(resp_blob->channel_name));
			if (req->offset == 0U && req->length == 0U) {
				lstp_uart_set_host_active(true);
			}
			if (offset + sizeof(struct lstp_uart_channel_config) <= LSTP_MAX_PAYLOAD_SIZE) {
				offset += sizeof(struct lstp_uart_channel_config);
			}
			break;

		default:
			LOG_WRN("Unsupported channel configuration read: %d", req->channel_id);
			return LSTP_STATUS_NOT_SUPPORTED;
	}

	*resp_len = offset;
	return LSTP_STATUS_SUCCESS;
}

static lstp_status_t handle_write_config(uint8_t *payload, size_t payload_len)
{
	lstp_status_t status;

	if (payload_len < sizeof(struct lstp_channel_config_write_request)) {
		return LSTP_STATUS_ERROR;
	}

	struct lstp_channel_config_write_request *req =
		(struct lstp_channel_config_write_request *)payload;
	size_t cfg_size = payload_len - sizeof(*req);

	if (!channel_id_supported(req->channel_id)) {
		return LSTP_STATUS_ERROR;
	}

	if (req->offset != 0) {
		return LSTP_STATUS_NOT_SUPPORTED;
	}

	if (cfg_size < sizeof(struct lstp_channel_config_blob)) {
		return LSTP_STATUS_ERROR;
	}

	struct lstp_channel_config_blob *cfg =
		(struct lstp_channel_config_blob *)(payload + sizeof(*req));
	status = write_channel_config_helper(req->channel_id, cfg, cfg_size);
	if (status == LSTP_STATUS_SUCCESS && req->channel_id == 4U) {
		lstp_uart_set_host_active(true);
	}

	return status;
}

static lstp_status_t handle_channel_0(struct lstp_hdr *hdr, uint8_t *payload, size_t payload_len,
		uint8_t *resp_buf, size_t *resp_len)
{
	lstp_management_cmd_t cmd = (lstp_management_cmd_t)hdr->cmd_status_code;

	switch (cmd) {
		case LSTP_MGMT_CMD_READ_CONFIG:
			return handle_read_config(hdr, payload, payload_len, resp_buf, resp_len);
		case LSTP_MGMT_CMD_WRITE_CONFIG:
			return handle_write_config(payload, payload_len);
		case LSTP_MGMT_CMD_LOCK:
			return LSTP_STATUS_NOT_SUPPORTED;
		default:
			LOG_WRN("Unknown management command: 0x%02x", cmd);
			return LSTP_STATUS_NOT_SUPPORTED;
	}
}

void lstp_router_receive(uint8_t *buffer, size_t len)
{
	if (len < sizeof(struct lstp_hdr)) {
		LOG_WRN("Received packet too small: %zu", len);
		return;
	}

	struct lstp_hdr *hdr = (struct lstp_hdr *)buffer;

	/* Ignore responses */
	if (hdr->cmd_status_code & LSTP_RESPONSE_BIT) {
		LOG_DBG("Ignoring response packet");
		return;
	}

	size_t payload_len = hdr->len_lsb | (hdr->len_msb << BYTE1_SHIFT);
	if (len < sizeof(struct lstp_hdr) + payload_len) {
		LOG_ERR("Invalid packet length: declared %zu, received %zu", payload_len, len - sizeof(struct lstp_hdr));
		return;
	}

	if (hdr->channel_id >= LSTP_NUM_CHANNELS) {
		LOG_ERR("Invalid channel id: %u", hdr->channel_id);
		return;
	}

	uint8_t *payload = buffer + sizeof(struct lstp_hdr);

	/* Allocate response buffer */
	uint8_t resp_buf[LSTP_MSG_SIZE];
	struct lstp_hdr *resp_hdr = (struct lstp_hdr *)resp_buf;
	uint8_t *resp_payload = resp_buf + sizeof(struct lstp_hdr);
	size_t resp_payload_len = 0;

	lstp_status_t status = LSTP_STATUS_NOT_SUPPORTED;

	LOG_DBG("Routing packet for channel %d", hdr->channel_id);

	/*
	 * Backward compatibility: Flashrom (NV_SMA_SPI) may use channel ID = 0
	 * in the request packet. For backward compatibility, treat channel 0
	 * commands 0x0..0x7 as SPI commands.
	 * Matches OpenSMA lstp_router.cpp receive_helper logic.
	 */
	uint8_t effective_channel_id = hdr->channel_id;
	if (hdr->channel_id == 0) {
		uint8_t cmd_code = hdr->cmd_status_code & LSTP_SPI_CMD_CODE_MASK;
		if (cmd_code <= LSTP_SPI_CMD_END) {
			effective_channel_id = 1;
			hdr->channel_id = 1;
			LOG_DBG("Backward compat: routing ch0 cmd 0x%02x to SPI", cmd_code);
		}
	}

	switch (effective_channel_id) {
		case 0: /* Management Channel */
			status = handle_channel_0(hdr, payload, payload_len, resp_payload, &resp_payload_len);

			/* Format and send Mgmt response synchronously */
			resp_hdr->channel_id = hdr->channel_id;
			resp_hdr->cmd_status_code = status | LSTP_RESPONSE_BIT;
			resp_hdr->len_lsb = resp_payload_len & LSB_MASK;
			resp_hdr->len_msb = (resp_payload_len >> BYTE1_SHIFT) & LSB_MASK;

			int ret = lstp_usb_send(resp_buf, sizeof(struct lstp_hdr) + resp_payload_len);
			if (ret < 0) {
				LOG_ERR("Failed to send OBMF management response: %d", ret);
			}
			break;

		case 1: /* SPI Channel (SPI1) — route to background task (thread context) */
			/*
			 * SPI transfers are blocking calls and cannot run in USB
			 * endpoint ISR context. Submit to the task queue.
			 */
			if (lstp_task_submit_req(buffer, len) < 0) {
				LOG_ERR("Task queue full, dropping SPI req");
			}
			break;

		case 2: /* I2C Channel (i2c6) — route to background task (thread context) */
			/*
			 * I2C transfers are blocking calls (i2c_write_read etc.) and
			 * cannot run in USB endpoint ISR context. Submit to the task
			 * queue, same as GPIO.
			 */
			if (lstp_task_submit_req(buffer, len) < 0) {
				LOG_ERR("Task queue full, dropping I2C req");
			}
			break;

		case 3: /* GPIO Hardware Channel */
			/* Submit the entire packet buffer to the background task queue */
			if (lstp_task_submit_req(buffer, len) < 0) {
				LOG_ERR("Task queue full, dropping GPIO req");
			}
			/* Do NOT send a synchronous response here, lstp_task handles it */
			break;

		case 4: /* UART Channel */
			if (lstp_task_submit_req(buffer, len) < 0) {
				LOG_ERR("Task queue full, dropping UART req");
			}
			break;

		default:
			LOG_WRN("Routing for channel %d not implemented", hdr->channel_id);
			break;
	}
}

int lstp_router_send_uart_data(const uint8_t *data, size_t len)
{
	uint8_t buf[LSTP_MSG_SIZE];
	struct lstp_hdr *hdr = (struct lstp_hdr *)buf;

	if (len > LSTP_MAX_PAYLOAD_SIZE) {
		return -EINVAL;
	}

	hdr->channel_id = 4;
	hdr->cmd_status_code = (uint8_t)LSTP_UART_CMD_WRITE;
	hdr->len_lsb = len & LSB_MASK;
	hdr->len_msb = (len >> BYTE1_SHIFT) & LSB_MASK;

	memcpy(buf + sizeof(*hdr), data, len);

	return lstp_usb_send(buf, sizeof(*hdr) + len);
}
```

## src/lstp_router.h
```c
/*
 * SPDX-FileCopyrightText: Copyright (c) 2026 NVIDIA CORPORATION & AFFILIATES.
 * SPDX-FileCopyrightText: Copyright (c) 2026 ASPEED Technology Inc.
 *
 * SPDX-License-Identifier: Apache-2.0
 *
 * Portions derived from NVIDIA OpenSMA (https://github.com/NVIDIA/OpenSMA),
 * licensed under Apache-2.0. Ported and modified by ASPEED.
 */

#ifndef LSTP_ROUTER_H
#define LSTP_ROUTER_H

#include <stdint.h>
#include <stddef.h>

/**
 * @brief Initialize the LSTP router subsystem and its internal channel state.
 */
void lstp_router_init(void);

/**
 * @brief Receive an LSTP packet from a transport layer (e.g. USB) and route it.
 *
 * If the packet is a valid request, it resolves the channel and processes it.
 * Responses are generated and sent back via lstp_usb_send().
 *
 * @param buffer Raw buffer containing the request
 * @param len    Length of the packet
 */
void lstp_router_receive(uint8_t *buffer, size_t len);

/**
 * @brief Send an unsolicited GPIO IRQ event packet to the host.
 *
 * Called from lstp_task's process_gpio_irq. Builds and transmits an IrqEvent
 * packet (lstp_hdr + lstp_gpio_irq_event_request) on the GPIO channel.
 * Mirrors LstpRouter::send_gpio_irq_event in OpenSMA.
 *
 * @param gpio_index Logical LSTP GPIO index that fired the interrupt
 * @param value      Current GPIO state (lstp_gpio_state_t)
 */
void lstp_router_send_gpio_irq_event(uint16_t gpio_index, uint8_t value);

/**
 * @brief Send UART RX bytes to the host on the LSTP UART channel.
 *
 * @param data UART payload bytes
 * @param len  Number of bytes in @p data
 * @return 0 on success, negative errno-style value on transport failure
 */
int lstp_router_send_uart_data(const uint8_t *data, size_t len);

#endif /* LSTP_ROUTER_H */
```

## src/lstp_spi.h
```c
/*
 * SPDX-FileCopyrightText: Copyright (c) 2026 NVIDIA CORPORATION & AFFILIATES.
 * SPDX-FileCopyrightText: Copyright (c) 2026 ASPEED Technology Inc.
 *
 * SPDX-License-Identifier: Apache-2.0
 *
 * Portions derived from NVIDIA OpenSMA (https://github.com/NVIDIA/OpenSMA),
 * licensed under Apache-2.0. Ported and modified by ASPEED.
 */

#ifndef LSTP_SPI_H
#define LSTP_SPI_H

#include <stdint.h>
#include <stddef.h>
#include "lstp_common.h"

/**
 * @brief Populate the cached SFDP data used by the SPI flash wrapper.
 *
 * Reads a bounded SFDP window from the CS0 flash device at startup so
 * runtime LSTP SFDP requests can be served from RAM.
 *
 * @return 0 on success, negative errno-style value on failure
 */
int lstp_spi_init(void);

/**
 * @brief Handle an incoming LSTP SPI channel request.
 *
 * Executes the SPI transfer synchronously (Config/Read/Write/WriteRead/PostedWrite)
 * and fills the response payload. Mirrors OpenSMA's LstpRouter::receive_spi and
 * Flashrom::handle_tx.
 *
 * @param channel_id  LSTP channel ID (used to select the SPI bus if multiple)
 * @param hdr         Pointer to the request LSTP header
 * @param payload     Pointer to the request payload (after header)
 * @param payload_len Length of the request payload in bytes
 * @param resp_payload Output buffer for the response payload (after header)
 * @param resp_payload_len Set to the number of bytes written to resp_payload
 * @param send_response Set to true when the caller should emit a solicited
 *                      response packet, false for side-effect-only commands
 * @return LSTP status code
 */
lstp_status_t lstp_spi_receive(uint8_t channel_id,
				struct lstp_hdr *hdr,
				uint8_t *payload, size_t payload_len,
				uint8_t *resp_payload, size_t *resp_payload_len,
				bool *send_response);

#endif /* LSTP_SPI_H */
```

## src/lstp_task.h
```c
/*
 * SPDX-FileCopyrightText: Copyright (c) 2026 NVIDIA CORPORATION & AFFILIATES.
 * SPDX-FileCopyrightText: Copyright (c) 2026 ASPEED Technology Inc.
 *
 * SPDX-License-Identifier: Apache-2.0
 *
 * Portions derived from NVIDIA OpenSMA (https://github.com/NVIDIA/OpenSMA),
 * licensed under Apache-2.0. Ported and modified by ASPEED.
 */

#ifndef LSTP_TASK_H
#define LSTP_TASK_H

#include <stdint.h>
#include <stddef.h>

/**
 * @brief Initialize the LSTP Background Task.
 *
 * Spawns the Zephyr thread and initializes the message queues used for
 * background processing of hardware commands.
 */
void lstp_task_init(void);

/**
 * @brief Submit a GPIO LSTP request to the background task.
 *
 * Called from the USB Rx ISR context (via lstp_router_receive). The packet is
 * copied into the task queue and processing happens asynchronously. The
 * response is sent via lstp_usb_send() from the task thread.
 *
 * @param buffer Raw buffer containing the request header + payload
 * @param len    Length of the packet
 * @return 0 if queued successfully, negative error code otherwise.
 */
int lstp_task_submit_req(uint8_t *buffer, size_t len);

/**
 * @brief Submit a GPIO IRQ event to the background task (ISR-safe).
 *
 * Called from a GPIO interrupt callback. Reads the current pin value,
 * enqueues an IRQ event, and wakes the task thread.
 *
 * @param gpio_index Logical LSTP GPIO index that fired the interrupt
 */
void lstp_task_submit_gpio_irq(uint16_t gpio_index);

#endif /* LSTP_TASK_H */
```

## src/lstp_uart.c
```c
/*
 * SPDX-FileCopyrightText: Copyright (c) 2026 NVIDIA CORPORATION & AFFILIATES.
 * SPDX-FileCopyrightText: Copyright (c) 2026 ASPEED Technology Inc.
 *
 * SPDX-License-Identifier: Apache-2.0
 *
 * Portions derived from NVIDIA OpenSMA (https://github.com/NVIDIA/OpenSMA),
 * licensed under Apache-2.0. Ported and modified by ASPEED.
 */

#include <zephyr/device.h>
#include <zephyr/drivers/uart.h>
#include <zephyr/irq.h>
#include <zephyr/logging/log.h>

#include "lstp_router.h"
#include "lstp_uart.h"

LOG_MODULE_REGISTER(lstp_uart, LOG_LEVEL_ERR);

static const struct device *lstp_uart3_dev;

static bool lstp_uart_host_active;

static void lstp_uart_forward_rx_bytes(const uint8_t *data, size_t len)
{
	int ret;

	if (!lstp_uart_host_active || len == 0U) {
		return;
	}

	ret = lstp_router_send_uart_data(data, len);
	if (ret < 0) {
		LOG_WRN("Failed to forward UART RX data: %d", ret);
	}
}

void lstp_uart_set_host_active(bool active)
{
	unsigned int key = irq_lock();

	lstp_uart_host_active = active;

	irq_unlock(key);
}

void shell_uart_mirror_tx_hook(const uint8_t *data, size_t len)
{
	ARG_UNUSED(data);
	ARG_UNUSED(len);
}

static void lstp_uart3_irq_handler(const struct device *dev, void *user_data)
{
	uint8_t buf[64];

	ARG_UNUSED(user_data);

	if (!uart_irq_update(dev)) {
		return;
	}

	while (uart_irq_rx_ready(dev)) {
		int rd = uart_fifo_read(dev, buf, sizeof(buf));

		if (rd <= 0) {
			break;
		}

		lstp_uart_forward_rx_bytes(buf, rd);
	}
}

int lstp_uart_init(void)
{
	lstp_uart3_dev = DEVICE_DT_GET(DT_NODELABEL(uart3));
	if (!device_is_ready(lstp_uart3_dev)) {
		LOG_ERR("uart3 device not ready");
		return -ENODEV;
	}

	uart_irq_callback_set(lstp_uart3_dev, lstp_uart3_irq_handler);
	uart_irq_rx_enable(lstp_uart3_dev);
	return 0;
}

lstp_status_t lstp_uart_receive(uint8_t channel_id,
				struct lstp_hdr *hdr,
				uint8_t *payload, size_t payload_len,
				uint8_t *resp_payload, size_t *resp_payload_len)
{
	lstp_uart_command_t cmd;

	ARG_UNUSED(channel_id);
	ARG_UNUSED(resp_payload);

	*resp_payload_len = 0;

	cmd = (lstp_uart_command_t)(hdr->cmd_status_code & ~LSTP_RESPONSE_BIT);
	if (cmd != LSTP_UART_CMD_WRITE) {
		return LSTP_STATUS_NOT_SUPPORTED;
	}

	/* No payload = connection open signal, mark host side active. */
	if (payload_len == 0U) {
		lstp_uart_host_active = true;
	}
	/* Has payload = TX data from host, send to uart3. */
	else if (lstp_uart3_dev != NULL && payload != NULL) {
		lstp_uart_host_active = true;
		for (size_t i = 0; i < payload_len; i++) {
			uart_poll_out(lstp_uart3_dev, payload[i]);
		}
	}

	return LSTP_STATUS_SUCCESS;
}
```

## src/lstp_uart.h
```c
/*
 * SPDX-FileCopyrightText: Copyright (c) 2026 NVIDIA CORPORATION & AFFILIATES.
 * SPDX-FileCopyrightText: Copyright (c) 2026 ASPEED Technology Inc.
 *
 * SPDX-License-Identifier: Apache-2.0
 *
 * Portions derived from NVIDIA OpenSMA (https://github.com/NVIDIA/OpenSMA),
 * licensed under Apache-2.0. Ported and modified by ASPEED.
 */

#ifndef LSTP_UART_H
#define LSTP_UART_H

#include <stddef.h>
#include <stdint.h>

#include "lstp_common.h"

#define LSTP_UART_MIRROR_BUF_SIZE 256U

int lstp_uart_init(void);
void lstp_uart_set_host_active(bool active);
void shell_uart_mirror_tx_hook(const uint8_t *data, size_t len);
lstp_status_t lstp_uart_receive(uint8_t channel_id,
				struct lstp_hdr *hdr,
				uint8_t *payload, size_t payload_len,
				uint8_t *resp_payload, size_t *resp_payload_len);

#endif /* LSTP_UART_H */
```
